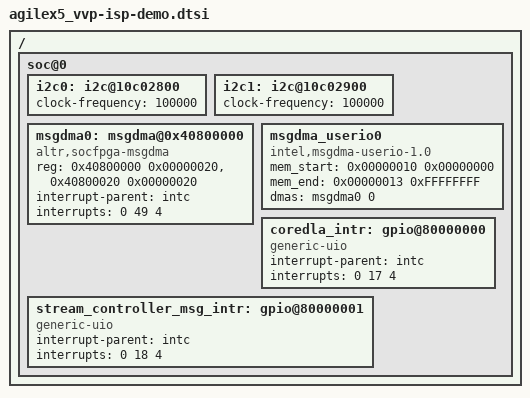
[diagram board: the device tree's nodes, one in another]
/*
* Add this piece of dtsi fragment in the file socfpga_agilex5_socdk.dts
* Compile it in the kernel along with socfpga_agilex5.dtsi
* LW bridge starts on 0x2000_0000
* Full bridge starts on 0x4000_0000
*/

/{
	soc@0 {

		i2c0: i2c@10c02800 {
			status = "okay";
			clock-frequency = <100000>;
		};

		i2c1: i2c@10c02900 {
			status = "okay";
			clock-frequency = <100000>;
		};

		msgdma0: msgdma@0x40800000 {
			status = "okay";
			compatible = "altr,socfpga-msgdma";
			reg = <0x40800000 0x00000020>,
				  <0x40800020 0x00000020>;
			reg-names = "csr", "desc";
			interrupt-parent = <&intc>;
			interrupts = <0 49 4>;
			#dma-cells = <1>;
		};		

		msgdma_userio0 {
			status = "okay";
			compatible = "intel,msgdma-userio-1.0";
			mem_start = <0x00000010 0x00000000>;
			mem_end = <0x00000013 0xFFFFFFFF>;
			reg-names = "emif";
			dmas = <&msgdma0 0>;
			dma-names = "rx";
		};

		coredla_intr: gpio@80000000 {
			compatible = "generic-uio";
			interrupt-parent = <&intc>;
			interrupts = <0 17 4>;
		};

		stream_controller_msg_intr: gpio@80000001 {
			compatible = "generic-uio";
			interrupt-parent = <&intc>;
			interrupts = <0 18 4>;
		};
	};
};
